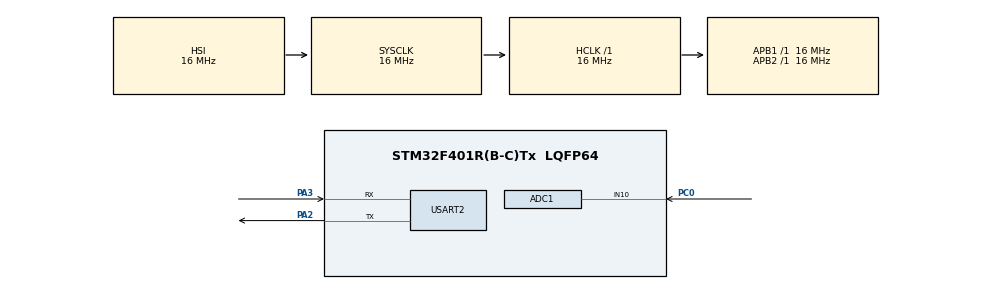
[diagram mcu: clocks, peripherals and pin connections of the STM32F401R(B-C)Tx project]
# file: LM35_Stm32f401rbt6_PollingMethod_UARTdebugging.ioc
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ADC1.Channel-0\#ChannelRegularConversion=ADC_CHANNEL_10
ADC1.NbrOfConversionFlag=1
ADC1.Rank-0\#ChannelRegularConversion=1
ADC1.SamplingTime-0\#ChannelRegularConversion=ADC_SAMPLETIME_480CYCLES
ADC1.master=1
Mcu.Family=STM32F4
Mcu.Name=STM32F401R(B-C)Tx
Mcu.Package=LQFP64
NVIC.PriorityGroup=NVIC_PRIORITYGROUP_4
PA13.Mode=Serial_Wire
PA13.Signal=SYS_JTMS-SWDIO
PA14.Mode=Serial_Wire
PA14.Signal=SYS_JTCK-SWCLK
PA2.Mode=Asynchronous
PA2.Signal=USART2_TX
PA3.Mode=Asynchronous
PA3.Signal=USART2_RX
PC0.Signal=ADCx_IN10
PC14-OSC32_IN.Mode=LSE-External-Oscillator
PC14-OSC32_IN.Signal=RCC_OSC32_IN
PC15-OSC32_OUT.Mode=LSE-External-Oscillator
PC15-OSC32_OUT.Signal=RCC_OSC32_OUT
PH0\ -\ OSC_IN.Mode=HSE-External-Oscillator
PH0\ -\ OSC_IN.Signal=RCC_OSC_IN
PH1\ -\ OSC_OUT.Mode=HSE-External-Oscillator
PH1\ -\ OSC_OUT.Signal=RCC_OSC_OUT
ProjectManager.HeapSize=0x200
ProjectManager.StackSize=0x400
ProjectManager.TargetToolchain=STM32CubeIDE
RCC.AHBFreq_Value=16000000
RCC.APB1Freq_Value=16000000
RCC.APB2Freq_Value=16000000
RCC.CortexFreq_Value=16000000
RCC.HSE_VALUE=25000000
RCC.HSI_VALUE=16000000
RCC.SYSCLKFreq_VALUE=16000000
RCC.VCOOutputFreq_Value=192000000
SH.ADCx_IN10.0=ADC1_IN10,IN10
USART2.VirtualMode=VM_ASYNC
board=custom

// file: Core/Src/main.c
/* ============================================================= */
/* 🧠 PROJECT: LM35 Temperature Sensor with UART Output (Polling) */
/* ============================================================= */

/*
 📌 Microcontroller  : STM32F401RBT6 (Cortex-M4)
 📌 Development Tool : STM32CubeIDE
 📌 Method Used      : ADC Polling + UART Transmission

 📡 SENSOR DETAILS:
 - Sensor           : LM35 Temperature Sensor
 - Output           : Analog Voltage (10mV per °C)
 - Example          : 25°C → 250mV (0.25V)

 🔌 PIN CONNECTIONS:
 - LM35 VCC         → 3.3V
 - LM35 GND         → GND
 - LM35 OUT         → PC0 (ADC1_IN10)

 📊 ADC CONFIGURATION:
 - ADC Instance     : ADC1
 - Channel          : Channel 10 (PC0)
 - Resolution       : 12-bit (0–4095)
 - Reference Voltage: 3.3V
 - Mode             : Polling (Manual start each time)

 📤 UART CONFIGURATION:
 - UART Instance    : USART2
 - TX Pin           : PA2
 - RX Pin           : PA3
 - Baud Rate        : 115200
 - Terminal         : minicom (Linux)

 🎯 PROJECT GOAL:
 - Read temperature from LM35 sensor
 - Convert analog signal → digital → voltage → temperature
 - Send temperature continuously to PC via UART

 */
/* ============================================================= */

/* USER CODE BEGIN Header */
/**
 ******************************************************************************
 * @file           : main.c
 * @brief          : Main program body
 ******************************************************************************
 * @attention
 *
 * Copyright (c) 2026 STMicroelectronics.
 * All rights reserved.
 *
 * This software is licensed under terms that can be found in the LICENSE file
 * in the root directory of this software component.
 * If no LICENSE file comes with this software, it is provided AS-IS.
 *
 ******************************************************************************
 */
/* USER CODE END Header */
#include "main.h"

/* USER CODE BEGIN Includes */
#include <stdio.h>
#include <string.h>
/* USER CODE END Includes */

ADC_HandleTypeDef hadc1;

UART_HandleTypeDef huart2;

void SystemClock_Config(void);
static void MX_GPIO_Init(void);
static void MX_ADC1_Init(void);
static void MX_USART2_UART_Init(void);
/* USER CODE BEGIN PFP */
char msg[50];
uint32_t adc_val;
float Temperature;
float Voltage;
/* USER CODE END PFP */

int main(void) {

	/* MCU Configuration--------------------------------------------------------*/

	/* Reset of all peripherals, Initializes the Flash interface and the Systick. */
	HAL_Init();

	/* Configure the system clock */
	SystemClock_Config();

	/* Initialize all configured peripherals */
	MX_GPIO_Init();
	MX_ADC1_Init();
	MX_USART2_UART_Init();

	/* Infinite loop */
	while (1) {

		/* USER CODE BEGIN 3 */

		/* ====================== 🔁 MAIN LOOP START ====================== */
		while (1) {
			// 🚀 Step 1: Start ADC conversion manually
			// Required because we are using polling (not continuous mode)
			HAL_ADC_Start(&hadc1);

			// ⏳ Step 2: Wait for ADC conversion to complete
			// Timeout = 100ms (prevents infinite blocking)
			if (HAL_ADC_PollForConversion(&hadc1, 100) == HAL_OK) {
				// 📥 Step 3: Read ADC digital value (0–4095)
				adc_val = HAL_ADC_GetValue(&hadc1);

				// 🔢 Step 4: Convert ADC value → Voltage
				// Formula: Voltage = (ADC_value / 4095) × 3.3V
				Voltage = (adc_val * 3.3f) / 4095.0f;

				// 🌡️ Step 5: Convert Voltage → Temperature
				// LM35: 10mV per °C → Temp = Voltage × 100
				Temperature = Voltage * 100.0f;

				// 📝 Step 6: Format temperature into string
				// %.2f → display 2 decimal points
				sprintf(msg, "Temp: %.2f C\r\n", Temperature);

				// 📤 Step 7: Transmit data via UART to PC terminal
				HAL_UART_Transmit(&huart2, (uint8_t*) msg, strlen(msg), 100);
			}

			// ⏱️ Step 8: Wait 1 second before next reading
			HAL_Delay(1000);
		}
		/* ====================== 🔁 MAIN LOOP END ====================== */
	}
	/* USER CODE END 3 */
}

void SystemClock_Config(void) {
	RCC_OscInitTypeDef RCC_OscInitStruct = { 0 };
	RCC_ClkInitTypeDef RCC_ClkInitStruct = { 0 };

	/** Configure the main internal regulator output voltage
	 */
	__HAL_RCC_PWR_CLK_ENABLE();
	__HAL_PWR_VOLTAGESCALING_CONFIG(PWR_REGULATOR_VOLTAGE_SCALE2);

	/** Initializes the RCC Oscillators according to the specified parameters
	 * in the RCC_OscInitTypeDef structure.
	 */
	RCC_OscInitStruct.OscillatorType = RCC_OSCILLATORTYPE_HSI;
	RCC_OscInitStruct.HSIState = RCC_HSI_ON;
	RCC_OscInitStruct.HSICalibrationValue = RCC_HSICALIBRATION_DEFAULT;
	RCC_OscInitStruct.PLL.PLLState = RCC_PLL_NONE;
	if (HAL_RCC_OscConfig(&RCC_OscInitStruct) != HAL_OK) {
		Error_Handler();
	}

	/** Initializes the CPU, AHB and APB buses clocks
	 */
	RCC_ClkInitStruct.ClockType = RCC_CLOCKTYPE_HCLK | RCC_CLOCKTYPE_SYSCLK
			| RCC_CLOCKTYPE_PCLK1 | RCC_CLOCKTYPE_PCLK2;
	RCC_ClkInitStruct.SYSCLKSource = RCC_SYSCLKSOURCE_HSI;
	RCC_ClkInitStruct.AHBCLKDivider = RCC_SYSCLK_DIV1;
	RCC_ClkInitStruct.APB1CLKDivider = RCC_HCLK_DIV1;
	RCC_ClkInitStruct.APB2CLKDivider = RCC_HCLK_DIV1;

	if (HAL_RCC_ClockConfig(&RCC_ClkInitStruct, FLASH_LATENCY_0) != HAL_OK) {
		Error_Handler();
	}
}

static void MX_ADC1_Init(void) {

	ADC_ChannelConfTypeDef sConfig = { 0 };

	/** Configure the global features of the ADC (Clock, Resolution, Data Alignment and number of conversion)
	 */
	hadc1.Instance = ADC1;
	hadc1.Init.ClockPrescaler = ADC_CLOCK_SYNC_PCLK_DIV2;
	hadc1.Init.Resolution = ADC_RESOLUTION_12B;
	hadc1.Init.ScanConvMode = DISABLE;
	hadc1.Init.ContinuousConvMode = DISABLE;
	hadc1.Init.DiscontinuousConvMode = DISABLE;
	hadc1.Init.ExternalTrigConvEdge = ADC_EXTERNALTRIGCONVEDGE_NONE;
	hadc1.Init.ExternalTrigConv = ADC_SOFTWARE_START;
	hadc1.Init.DataAlign = ADC_DATAALIGN_RIGHT;
	hadc1.Init.NbrOfConversion = 1;
	hadc1.Init.DMAContinuousRequests = DISABLE;
	hadc1.Init.EOCSelection = ADC_EOC_SINGLE_CONV;
	if (HAL_ADC_Init(&hadc1) != HAL_OK) {
		Error_Handler();
	}

	/** Configure for the selected ADC regular channel its corresponding rank in the sequencer and its sample time.
	 */
	sConfig.Channel = ADC_CHANNEL_10;
	sConfig.Rank = 1;
	sConfig.SamplingTime = ADC_SAMPLETIME_480CYCLES;
	if (HAL_ADC_ConfigChannel(&hadc1, &sConfig) != HAL_OK) {
		Error_Handler();
	}

}

static void MX_USART2_UART_Init(void) {

	huart2.Instance = USART2;
	huart2.Init.BaudRate = 115200;
	huart2.Init.WordLength = UART_WORDLENGTH_8B;
	huart2.Init.StopBits = UART_STOPBITS_1;
	huart2.Init.Parity = UART_PARITY_NONE;
	huart2.Init.Mode = UART_MODE_TX_RX;
	huart2.Init.HwFlowCtl = UART_HWCONTROL_NONE;
	huart2.Init.OverSampling = UART_OVERSAMPLING_16;
	if (HAL_UART_Init(&huart2) != HAL_OK) {
		Error_Handler();
	}

}

static void MX_GPIO_Init(void) {

	/* GPIO Ports Clock Enable */
	__HAL_RCC_GPIOC_CLK_ENABLE();
	__HAL_RCC_GPIOH_CLK_ENABLE();
	__HAL_RCC_GPIOA_CLK_ENABLE();

}

void Error_Handler(void) {
	__disable_irq();
	while (1) {
	}
}
